VERSION ""

NS_ :

BS_:

BU_: Gateway ECU DMS OMS

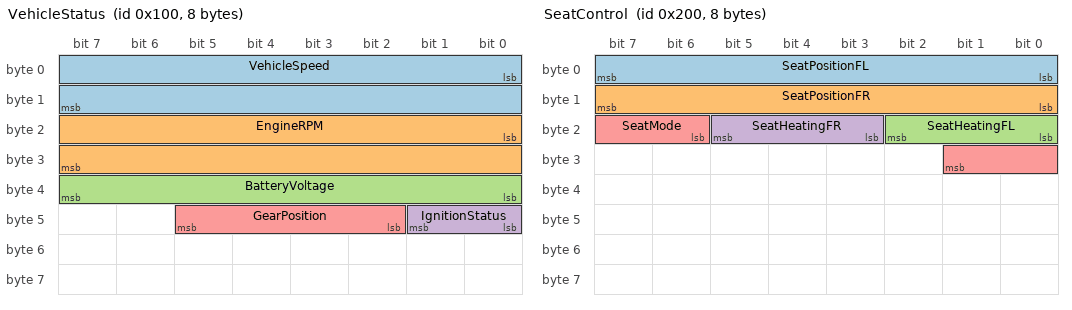
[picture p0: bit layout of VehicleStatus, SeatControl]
BO_ 256 VehicleStatus: 8 Gateway
 SG_ VehicleSpeed : 0|16@1+ (0.01,0) [0|655.35] "km/h" Vector__XXX
 SG_ EngineRPM : 16|16@1+ (1,0) [0|16383] "rpm" Vector__XXX
 SG_ BatteryVoltage : 32|8@1+ (0.1,0) [0|25.5] "V" Vector__XXX
 SG_ IgnitionStatus : 40|2@1+ (1,0) [0|3] "" Vector__XXX
 SG_ GearPosition : 42|4@1+ (1,0) [0|15] "" Vector__XXX

BO_ 512 SeatControl: 8 ECU
 SG_ SeatPositionFL : 0|8@1+ (1,0) [0|255] "" Vector__XXX
 SG_ SeatPositionFR : 8|8@1+ (1,0) [0|255] "" Vector__XXX
 SG_ SeatHeatingFL : 16|3@1+ (1,0) [0|7] "" Vector__XXX
 SG_ SeatHeatingFR : 19|3@1+ (1,0) [0|7] "" Vector__XXX
 SG_ SeatMode : 22|4@1+ (1,0) [0|15] "" Vector__XXX

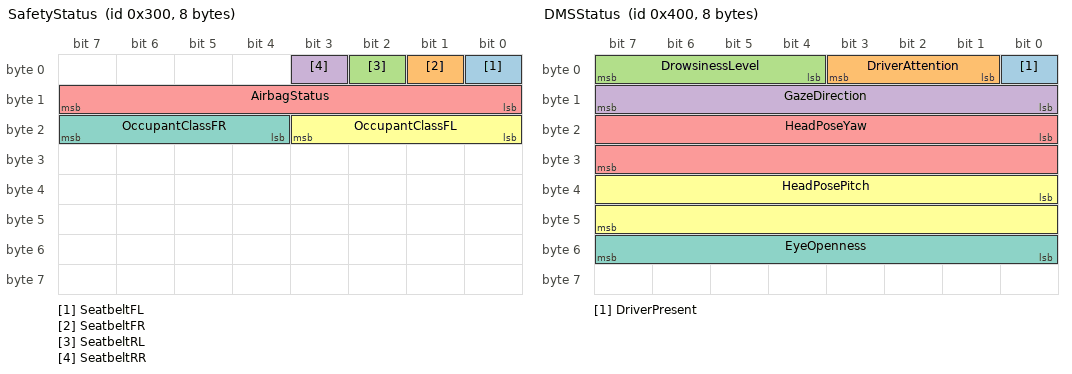
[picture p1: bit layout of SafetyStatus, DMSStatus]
BO_ 768 SafetyStatus: 8 ECU
 SG_ SeatbeltFL : 0|1@1+ (1,0) [0|1] "" Vector__XXX
 SG_ SeatbeltFR : 1|1@1+ (1,0) [0|1] "" Vector__XXX
 SG_ SeatbeltRL : 2|1@1+ (1,0) [0|1] "" Vector__XXX
 SG_ SeatbeltRR : 3|1@1+ (1,0) [0|1] "" Vector__XXX
 SG_ AirbagStatus : 8|8@1+ (1,0) [0|255] "" Vector__XXX
 SG_ OccupantClassFL : 16|4@1+ (1,0) [0|15] "" Vector__XXX
 SG_ OccupantClassFR : 20|4@1+ (1,0) [0|15] "" Vector__XXX

BO_ 1024 DMSStatus: 8 DMS
 SG_ DriverPresent : 0|1@1+ (1,0) [0|1] "" Vector__XXX
 SG_ DriverAttention : 1|3@1+ (1,0) [0|7] "" Vector__XXX
 SG_ DrowsinessLevel : 4|4@1+ (1,0) [0|15] "" Vector__XXX
 SG_ GazeDirection : 8|8@1+ (1,0) [0|255] "deg" Vector__XXX
 SG_ HeadPoseYaw : 16|16@1- (0.1,0) [-180|180] "deg" Vector__XXX
 SG_ HeadPosePitch : 32|16@1- (0.1,0) [-90|90] "deg" Vector__XXX
 SG_ EyeOpenness : 48|8@1+ (0.5,0) [0|100] "%" Vector__XXX

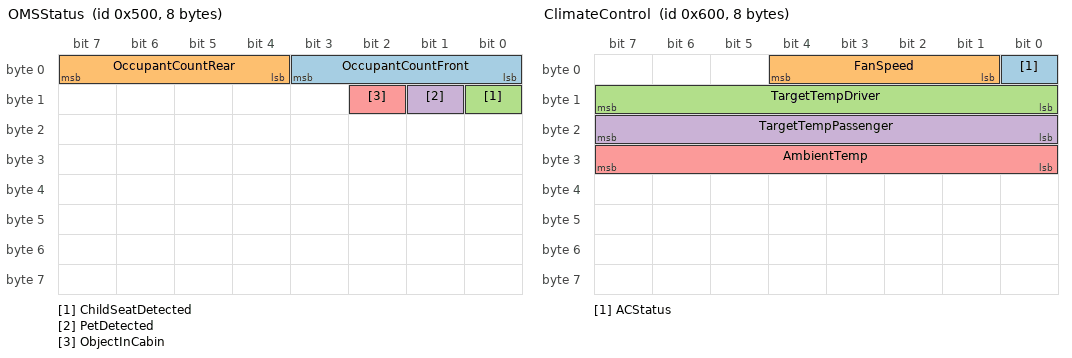
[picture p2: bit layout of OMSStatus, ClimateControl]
BO_ 1280 OMSStatus: 8 OMS
 SG_ OccupantCountFront : 0|4@1+ (1,0) [0|4] "" Vector__XXX
 SG_ OccupantCountRear : 4|4@1+ (1,0) [0|4] "" Vector__XXX
 SG_ ChildSeatDetected : 8|1@1+ (1,0) [0|1] "" Vector__XXX
 SG_ PetDetected : 9|1@1+ (1,0) [0|1] "" Vector__XXX
 SG_ ObjectInCabin : 10|1@1+ (1,0) [0|1] "" Vector__XXX

BO_ 1536 ClimateControl: 8 ECU
 SG_ ACStatus : 0|1@1+ (1,0) [0|1] "" Vector__XXX
 SG_ FanSpeed : 1|4@1+ (1,0) [0|15] "" Vector__XXX
 SG_ TargetTempDriver : 8|8@1+ (0.5,14) [14|32] "C" Vector__XXX
 SG_ TargetTempPassenger : 16|8@1+ (0.5,14) [14|32] "C" Vector__XXX
 SG_ AmbientTemp : 24|8@1- (0.5,-40) [-40|87.5] "C" Vector__XXX

CM_ BO_ 256 "Vehicle status message from gateway";
CM_ BO_ 512 "Seat control and status";
CM_ BO_ 768 "Safety system status";
CM_ BO_ 1024 "Driver Monitoring System status";
CM_ BO_ 1280 "Occupant Monitoring System status";
CM_ BO_ 1536 "Climate control status";

CM_ SG_ 256 VehicleSpeed "Vehicle speed from wheel sensors";
CM_ SG_ 256 EngineRPM "Engine rotations per minute";
CM_ SG_ 512 SeatMode "0=Normal, 1=Comfort, 2=ZeroG, 3=Entry/Exit";
CM_ SG_ 1024 DriverAttention "0=Unknown, 1=Attentive, 2=Distracted, 3=Drowsy";
CM_ SG_ 1024 DrowsinessLevel "0=Alert to 15=Very Drowsy";

VAL_ 256 IgnitionStatus 0 "Off" 1 "Accessory" 2 "On" 3 "Start";
VAL_ 256 GearPosition 0 "Park" 1 "Reverse" 2 "Neutral" 3 "Drive" 4 "Sport" 5 "Manual";
VAL_ 512 SeatMode 0 "Normal" 1 "Comfort" 2 "ZeroG" 3 "Entry" 4 "Exit";
VAL_ 768 OccupantClassFL 0 "Empty" 1 "Child" 2 "Adult_Small" 3 "Adult_Medium" 4 "Adult_Large";
VAL_ 1024 DriverAttention 0 "Unknown" 1 "Attentive" 2 "Distracted" 3 "Drowsy" 4 "Asleep";
